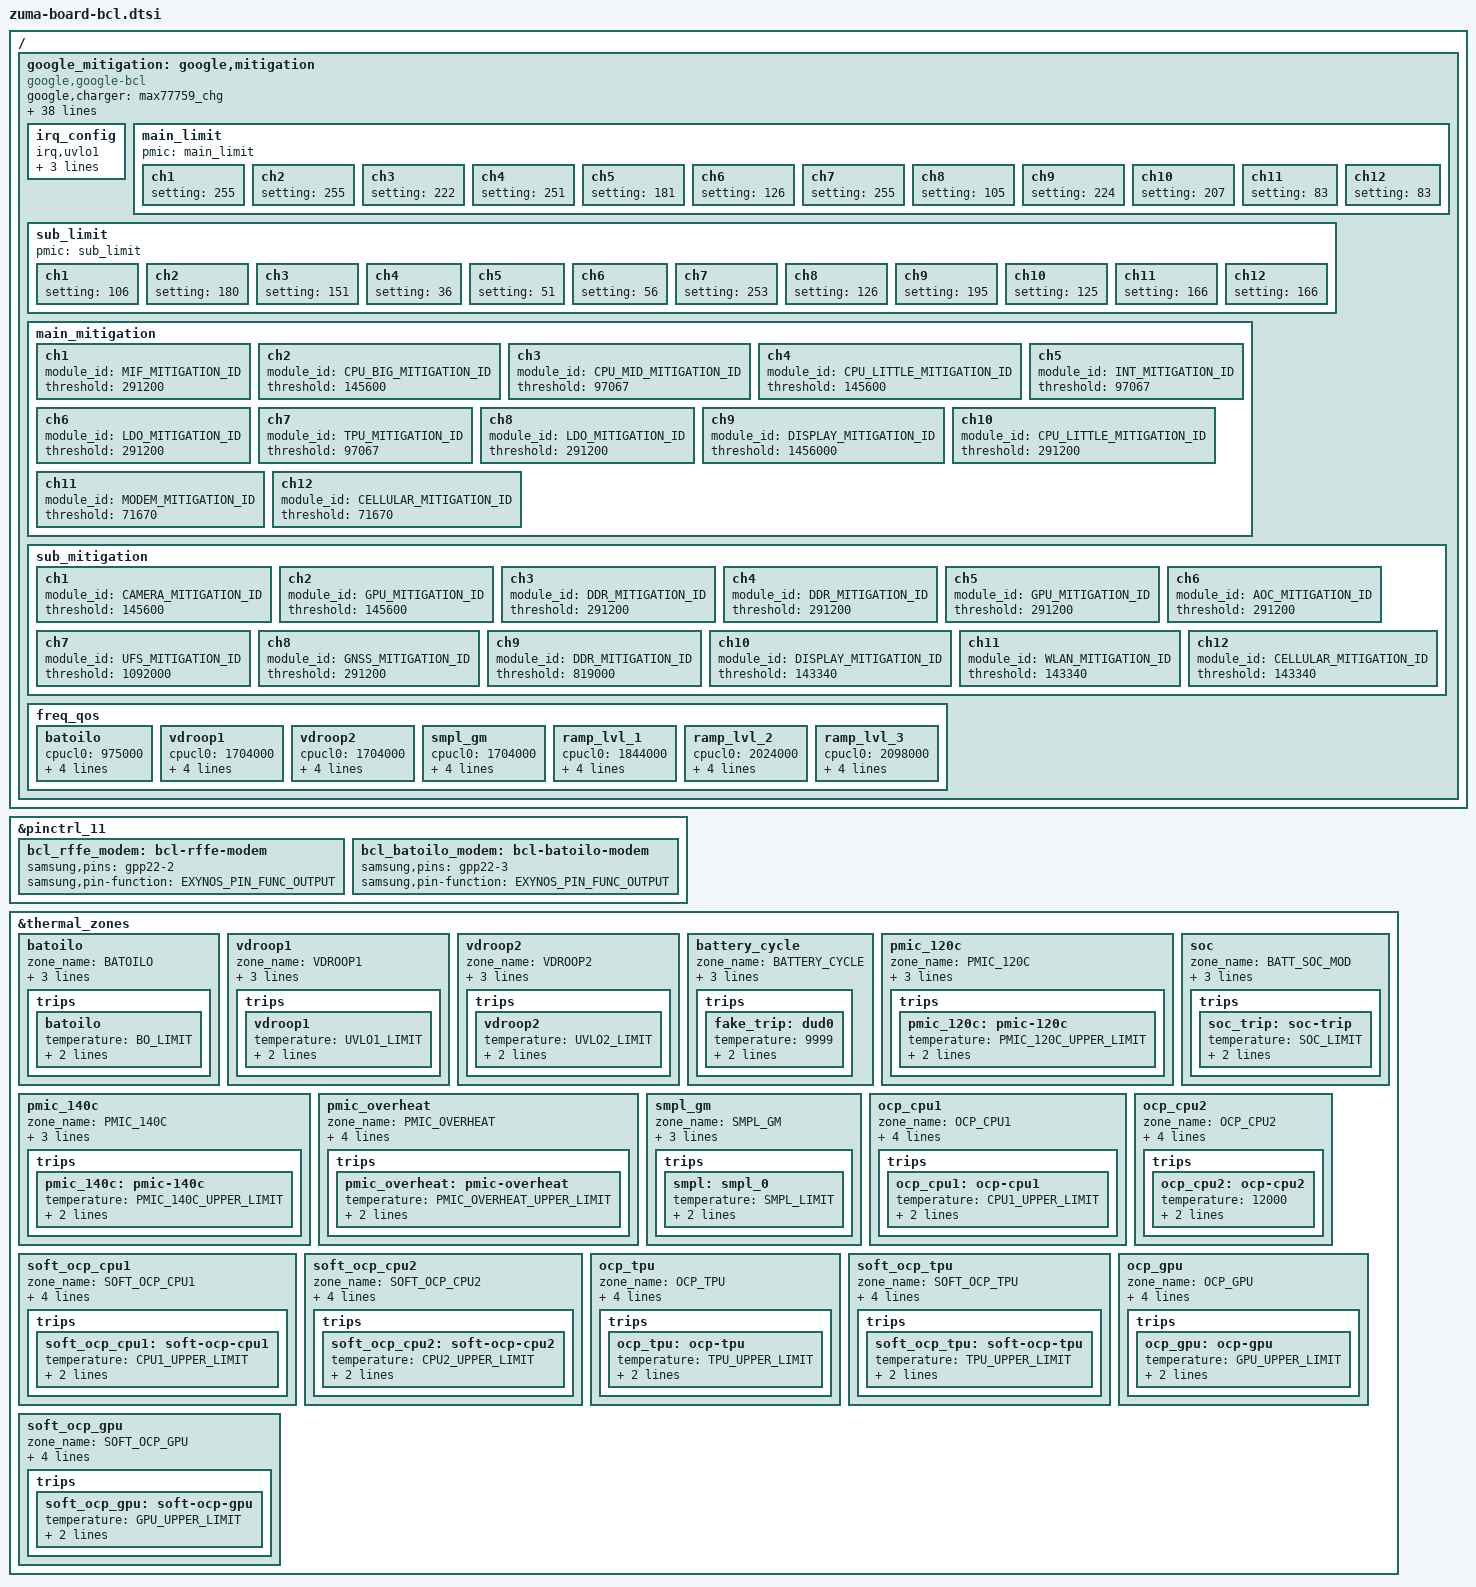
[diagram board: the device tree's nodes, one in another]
// SPDX-License-Identifier: GPL-2.0-only
/*
 * Google Zuma specific bcl device tree source
 *
 * Copyright (c) 2024 Google, LLC
 *		https://www.google.com
 */

#include <dt-bindings/thermal/thermal.h>
#include <dt-bindings/soc/google/zuma-bcl.h>

&pinctrl_11 {
	bcl_rffe_modem: bcl-rffe-modem {
		samsung,pins = "gpp22-2";
		samsung,pin-function = <EXYNOS_PIN_FUNC_OUTPUT>;
	};
	bcl_batoilo_modem: bcl-batoilo-modem {
		samsung,pins = "gpp22-3";
		samsung,pin-function = <EXYNOS_PIN_FUNC_OUTPUT>;
	};
};

/ {
	fragment@battery {
		target-path = "/";
		__overlay__ {
			google_mitigation: google,mitigation {
				compatible = "google,google-bcl";
				#thermal-sensor-cells = <1>;
				google,charger = <&max77759_chg>;
				google,pmic = <&max77759_chg>;
				google,power-supply = <&max77759_fg>;
				google,main-power = <&s2mpg14mfd>;
				google,sub-power = <&s2mpg15mfd>;
				ppm_settings = <0>;
				lit_mpmm_settings = <0x1AA>;
				mid_mpmm_settings = <0x1AA>;
				big_mpmm_settings = <0x6>;
				mpmm_en = <0x1f0>;
				tpu_con_heavy = <0xfff041c1>;
				tpu_con_light = <0xfff041c3>;
				tpu_clkdivstep = <0x1>;
				gpu_con_heavy = <0xfff04381>;
				gpu_con_light = <0xfff041c3>;
				cpu2_con_heavy = <0xfff041c0>;
				cpu2_con_light = <0xfff041c3>;
				cpu1_con_heavy = <0xfff041c0>;
				cpu1_con_light = <0xfff041c3>;
				gpu_clkdivstep = <0x1>;
				cpu2_clkdivstep = <0x1>;
				cpu1_clkdivstep = <0x1>;
				cpu0_clkdivstep = <0x1>;
				aur_clkdivstep = <0x1>;
				batoilo_lower = <3800>;
				batoilo_upper = <6800>;
				odpm_ratio = <3>;
				gpios = <&gpa9 5 GPIO_ACTIVE_HIGH>,		/* VDROOP1 */
					<&gpa9 6 GPIO_ACTIVE_HIGH>,		/* VDROOP2 */
					<&gpp22 2 GPIO_ACTIVE_HIGH>,
					<&gpp22 3 GPIO_ACTIVE_HIGH>;
				rffe_channel = <11>;
				pinctrl-names = "bcl-rffe-modem", "bcl-batoilo-modem";
				pinctrl-0 = <&bcl_rffe_modem>;
				pinctrl-1 = <&bcl_batoilo_modem>;
				cpu0_cluster = <0>;
				cpu1_cluster = <4>;
				cpu2_cluster = <8>;
				uvlo1_det = <0x0>;   /* 0us */
				uvlo2_det = <0x0>;   /* 0us */
				batoilo_det = <0x1>;   /* 30us */
				non_monitored_module_ids = <AUDIO_MITIGATION_ID HAPTICS_MITIGATION_ID>;

				irq_config {
					irq,uvlo1;
					irq,uvlo2;
					irq,batoilo;
					irq,smpl_warn;
					/* Disabled IRQ
					* irq,ocp_cpu1;
					* irq,ocp_cpu2;
					* irq,ocp_tpu;
					* irq,ocp_gpu;
					* irq,soft_ocp_cpu1;
					* irq,soft_ocp_cpu2;
					* irq,soft_ocp_tpu;
					* irq,soft_ocp_gpu;
					*/
				};
				main_limit {
					pmic = "main_limit";
					ch1 { setting = <255>; };
					ch2 { setting = <255>; };
					ch3 { setting = <222>; };
					ch4 { setting = <251>; };
					ch5 { setting = <181>; };
					ch6 { setting = <126>; };
					ch7 { setting = <255>; };
					ch8 { setting = <105>; };
					ch9 { setting = <224>; };
					ch10 { setting = <207>; };
					ch11 { setting = <83>; };
					ch12 { setting = <83>; };
				};
				sub_limit {
					pmic = "sub_limit";
					ch1 { setting = <106>; };
					ch2 { setting = <180>; };
					ch3 { setting = <151>; };
					ch4 { setting = <36>; };
					ch5 { setting = <51>; };
					ch6 { setting = <56>; };
					ch7 { setting = <253>; };
					ch8 { setting = <126>; };
					ch9 { setting = <195>; };
					ch10 { setting = <125>; };
					ch11 { setting = <166>; };
					ch12 { setting = <166>; };
				};
				main_mitigation {
					ch1 {
						module_id = <MIF_MITIGATION_ID>;
						threshold = <291200>; /* ODPM LPF RAW */
					};
					ch2 {
						module_id = <CPU_BIG_MITIGATION_ID>;
						threshold = <145600>;
					};
					ch3 {
						module_id = <CPU_MID_MITIGATION_ID>;
						threshold = <97067>;
					};
					ch4 {
						module_id = <CPU_LITTLE_MITIGATION_ID>;
						threshold = <145600>;
					};
					ch5 {
						module_id = <INT_MITIGATION_ID>;
						threshold = <97067>;
					};
					ch6 {
						module_id = <LDO_MITIGATION_ID>;
						threshold = <291200>;
					};
					ch7 {
						module_id = <TPU_MITIGATION_ID>;
						threshold = <97067>;
					};
					ch8 {
						module_id = <LDO_MITIGATION_ID>;
						threshold = <291200>;
					};
					ch9 {
						module_id = <DISPLAY_MITIGATION_ID>;
						threshold = <1456000>;
					};
					ch10 {
						module_id = <CPU_LITTLE_MITIGATION_ID>;
						threshold = <291200>;
					};
					ch11 {
						module_id = <MODEM_MITIGATION_ID>;
						threshold = <71670>;
					};
					ch12 {
						module_id = <CELLULAR_MITIGATION_ID>;
						threshold = <71670>;
					};
				};
				sub_mitigation {
					ch1 {
						module_id = <CAMERA_MITIGATION_ID>;
						threshold = <145600>; /* ODPM LPF RAW */
					};
					ch2 {
						module_id = <GPU_MITIGATION_ID>;
						threshold = <145600>;
					};
					ch3 {
						module_id = <DDR_MITIGATION_ID>;
						threshold = <291200>;
					};
					ch4 {
						module_id = <DDR_MITIGATION_ID>;
						threshold = <291200>;
					};
					ch5 {
						module_id = <GPU_MITIGATION_ID>;
						threshold = <291200>;
					};
					ch6 {
						module_id = <AOC_MITIGATION_ID>;
						threshold = <291200>;
					};
					ch7 {
						module_id = <UFS_MITIGATION_ID>;
						threshold = <1092000>;
					};
					ch8 {
						module_id = <GNSS_MITIGATION_ID>;
						threshold = <291200>;
					};
					ch9 {
						module_id = <DDR_MITIGATION_ID>;
						threshold = <819000>;
					};
					ch10 {
						module_id = <DISPLAY_MITIGATION_ID>;
						threshold = <143340>;
					};
					ch11 {
						module_id = <WLAN_MITIGATION_ID>;
						threshold = <143340>;
					};
					ch12 {
						module_id = <CELLULAR_MITIGATION_ID>;
						threshold = <143340>;
					};
				};
				freq_qos {
					batoilo {
						cpucl0 = <975000>;
						cpucl1 = <1221000>;
						cpucl2 = <1557000>;
						gpu = <723000>;
						tpu = <845000>;
					};
					vdroop1 {
						cpucl0 = <1704000>;
						cpucl1 = <1836000>;
						cpucl2 = <2294000>;
						gpu = <890000>;
						tpu = <845000>;
					};
					vdroop2 {
						cpucl0 = <1704000>;
						cpucl1 = <1836000>;
						cpucl2 = <2294000>;
						gpu = <649000>;
						tpu = <627000>;
					};
					smpl_gm {
						cpucl0 = <1704000>;
						cpucl1 = <1836000>;
						cpucl2 = <2294000>;
						gpu = <649000>;
						tpu = <627000>;
					};
					ramp_lvl_1 {
						cpucl0 = <1844000>;
						cpucl1 = <1999000>;
						cpucl2 = <2409000>;
						gpu = <890000>;
						tpu = <845000>;
					};
					ramp_lvl_2 {
						cpucl0 = <2024000>;
						cpucl1 = <2130000>;
						cpucl2 = <2687000>;
						gpu = <890000>;
						tpu = <845000>;
					};
					ramp_lvl_3 {
						cpucl0 = <2098000>;
						cpucl1 = <2352000>;
						cpucl2 = <2914000>;
						gpu = <890000>;
						tpu = <845000>;
					};
				};
			};
		};
	};
};

/* Thermal Zones */
&thermal_zones {
	batoilo {
		zone_name  = "BATOILO";
		polling-delay-passive = <THERMAL_DELAY_INIT_MS>;
		polling-delay = <0>;
		thermal-sensors = <&google_mitigation BATOILO>;
		trips {
			batoilo: batoilo{
				temperature = <BO_LIMIT>;
				hysteresis = <THERMAL_HYST_LEVEL>;
				type = "passive";
			};
		};
	};

	vdroop1 {
		zone_name  = "VDROOP1";
		polling-delay-passive = <THERMAL_DELAY_INIT_MS>;
		polling-delay = <0>;
		thermal-sensors = <&google_mitigation UVLO1>;
		trips {
			vdroop1: vdroop1{
				temperature = <UVLO1_LIMIT>;
				hysteresis = <THERMAL_HYST_LEVEL>;
				type = "passive";
			};
		};
	};

	vdroop2 {
		zone_name  = "VDROOP2";
		polling-delay-passive = <THERMAL_DELAY_INIT_MS>;
		polling-delay = <0>;
		thermal-sensors = <&google_mitigation UVLO2>;
		trips {
			vdroop2: vdroop2{
				temperature = <UVLO2_LIMIT>;
				hysteresis = <THERMAL_HYST_LEVEL>;
				type = "passive";
			};
		};
	};

	battery_cycle {
		zone_name  = "BATTERY_CYCLE";
		polling-delay-passive = <100>;
		polling-delay = <0>;
		thermal-sensors = <&google_battery>;

		/* TODO(b/251537418): fix this trips entry since it's required */
		trips {
			fake_trip:dud0 {
			temperature = <9999>;
			hysteresis = <100>;
			type = "passive";
			};
		};
	};

	pmic_120c {
		zone_name  = "PMIC_120C";
		polling-delay-passive = <THERMAL_DELAY_INIT_MS>;
		polling-delay = <0>;
		thermal-sensors = <&google_mitigation PMIC_120C>;
		trips {
			pmic_120c: pmic-120c {
				temperature = <PMIC_120C_UPPER_LIMIT>;
				hysteresis = <THERMAL_HYST_LEVEL>;
				type = "passive";
			};
		};
	};

	pmic_140c {
		zone_name  = "PMIC_140C";
		polling-delay-passive = <THERMAL_DELAY_INIT_MS>;
		polling-delay = <0>;
		thermal-sensors = <&google_mitigation PMIC_140C>;
		trips {
			pmic_140c: pmic-140c {
				temperature = <PMIC_140C_UPPER_LIMIT>;
				hysteresis = <THERMAL_HYST_LEVEL>;
				type = "passive";
			};
		};
	};

	pmic_overheat {
		zone_name  = "PMIC_OVERHEAT";
		polling-delay-passive = <THERMAL_DELAY_INIT_MS>;
		polling-delay = <0>;
		thermal-sensors = <&google_mitigation PMIC_OVERHEAT>;
		trips {
			pmic_overheat: pmic-overheat{
				temperature = <PMIC_OVERHEAT_UPPER_LIMIT>;
				hysteresis = <THERMAL_HYST_LEVEL>;
				type = "passive";
			};
		};
	};

	soc {
		zone_name  = "BATT_SOC_MOD";
		polling-delay-passive = <0>;
		polling-delay = <0>;
		thermal-sensors = <&google_mitigation PMIC_SOC>;

		trips {
			soc_trip:soc-trip {
				temperature = <SOC_LIMIT>;
				hysteresis = <0>;
				type = "passive";
			};
		};
	};

	smpl_gm {
		zone_name  = "SMPL_GM";
		polling-delay-passive = <THERMAL_DELAY_INIT_MS>;
		polling-delay = <0>;
		thermal-sensors = <&google_mitigation SMPL_WARN>;

		trips {
			smpl:smpl_0 {
				temperature = <SMPL_LIMIT>;
				hysteresis = <THERMAL_HYST_LEVEL>;
				type = "passive";
			};
		};
	};
	ocp_cpu1 {
		zone_name  = "OCP_CPU1";
		polling-delay-passive = <100>;
		polling-delay = <0>;
		thermal-sensors = <&google_mitigation OCP_WARN_CPUCL1>;

		trips {
			ocp_cpu1:ocp-cpu1 {
				temperature = <CPU1_UPPER_LIMIT>;
				hysteresis = <THERMAL_HYST_LEVEL>;
				type = "passive";
			};
		};
	};
	ocp_cpu2 {
		zone_name  = "OCP_CPU2";
		polling-delay-passive = <100>;
		polling-delay = <0>;
		thermal-sensors = <&google_mitigation OCP_WARN_CPUCL2>;

		trips {
			ocp_cpu2:ocp-cpu2 {
				temperature = <12000>;
				hysteresis = <THERMAL_HYST_LEVEL>;
				type = "passive";
			};
		};
	};
	soft_ocp_cpu1 {
		zone_name  = "SOFT_OCP_CPU1";
		polling-delay-passive = <100>;
		polling-delay = <0>;
		thermal-sensors = <&google_mitigation SOFT_OCP_WARN_CPUCL1>;

		trips {
			soft_ocp_cpu1:soft-ocp-cpu1 {
				temperature = <CPU1_UPPER_LIMIT>;
				hysteresis = <THERMAL_HYST_LEVEL>;
				type = "passive";
			};
		};
	};
	soft_ocp_cpu2 {
		zone_name  = "SOFT_OCP_CPU2";
		polling-delay-passive = <100>;
		polling-delay = <0>;
		thermal-sensors = <&google_mitigation SOFT_OCP_WARN_CPUCL2>;

		trips {
			soft_ocp_cpu2:soft-ocp-cpu2 {
				temperature = <CPU2_UPPER_LIMIT>;
				hysteresis = <THERMAL_HYST_LEVEL>;
				type = "passive";
			};
		};
	};
	ocp_tpu {
		zone_name  = "OCP_TPU";
		polling-delay-passive = <100>;
		polling-delay = <0>;
		thermal-sensors = <&google_mitigation OCP_WARN_TPU>;

		trips {
			ocp_tpu:ocp-tpu{
				temperature = <TPU_UPPER_LIMIT>;
				hysteresis = <THERMAL_HYST_LEVEL>;
				type = "passive";
			};
		};
	};
	soft_ocp_tpu {
		zone_name  = "SOFT_OCP_TPU";
		polling-delay-passive = <100>;
		polling-delay = <0>;
		thermal-sensors = <&google_mitigation SOFT_OCP_WARN_TPU>;

		trips {
			soft_ocp_tpu:soft-ocp-tpu {
				temperature = <TPU_UPPER_LIMIT>;
				hysteresis = <THERMAL_HYST_LEVEL>;
				type = "passive";
			};
		};
	};
	ocp_gpu {
		zone_name  = "OCP_GPU";
		polling-delay-passive = <100>;
		polling-delay = <0>;
		thermal-sensors = <&google_mitigation OCP_WARN_GPU>;

		trips {
			ocp_gpu:ocp-gpu{
				temperature = <GPU_UPPER_LIMIT>;
				hysteresis = <THERMAL_HYST_LEVEL>;
				type = "passive";
			};
		};
	};
	soft_ocp_gpu {
		zone_name  = "SOFT_OCP_GPU";
		polling-delay-passive = <100>;
		polling-delay = <0>;
		thermal-sensors = <&google_mitigation SOFT_OCP_WARN_GPU>;

		trips {
			soft_ocp_gpu:soft-ocp-gpu {
				temperature = <GPU_UPPER_LIMIT>;
				hysteresis = <THERMAL_HYST_LEVEL>;
				type = "passive";
			};
		};
	};
};
